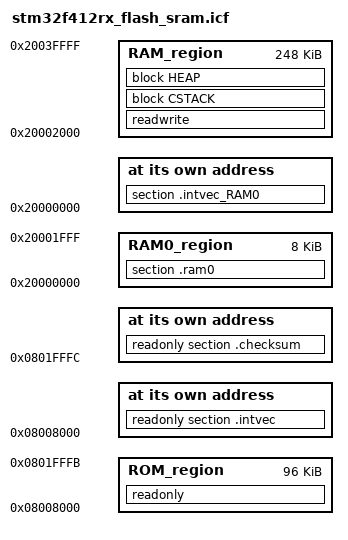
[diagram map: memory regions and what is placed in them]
/*###ICF### Section handled by ICF editor, don't touch! ****/
/*-Editor annotation file-*/
/* IcfEditorFile="$TOOLKIT_DIR$\config\ide\IcfEditor\cortex_v1_0.xml" */
/*-Specials-*/
define symbol __ICFEDIT_intvec_start__ = 0x08008000;
define symbol RAM0_intvec_start        = 0x20000000;

/*-Memory Regions-*/
define symbol __ICFEDIT_region_ROM_start__  = 0x08008000;
define symbol __ICFEDIT_region_ROM_end__    = 0x0801FFFB;
define symbol __ICFEDIT_region_RAM_start__  = 0x20002000;
define symbol __ICFEDIT_region_RAM_end__    = 0x2003FFFF;
define symbol __ICFEDIT_region_RAM0_start__ = 0x20000000;
define symbol __ICFEDIT_region_RAM0_end__   = 0x20001FFF;

/*-Sizes-*/
define symbol __ICFEDIT_size_cstack__ = 0x1400;
define symbol __ICFEDIT_size_heap__   = 0x1200;
/**** End of ICF editor section. ###ICF###*/


define memory mem with size = 4G;
define region ROM_region       = mem:[from __ICFEDIT_region_ROM_start__   to __ICFEDIT_region_ROM_end__];
define region RAM_region       = mem:[from __ICFEDIT_region_RAM_start__   to __ICFEDIT_region_RAM_end__];
define region RAM0_region      = mem:[from __ICFEDIT_region_RAM0_start__   to __ICFEDIT_region_RAM0_end__];

define block CSTACK         with alignment = 8, size = __ICFEDIT_size_cstack__   { };
define block HEAP           with alignment = 8, size = __ICFEDIT_size_heap__     { };

/*initialize by copy { readonly, readwrite };*/
initialize by copy { readwrite,
					section .ram0,
					section .intvec,
					section .intvec_RAM0,
					ro object stm32f4xx_it.o ,
					ro object *.o
					}
					except{
					ro object bl_header.o
					};
do not initialize  { section .noinit };

place at address mem:__ICFEDIT_intvec_start__ { readonly section .intvec };
place at address mem:RAM0_intvec_start { section .intvec_RAM0 };

place in ROM_region   { readonly };
place in RAM_region   { readwrite,
                        block CSTACK, block HEAP };
place in RAM0_region   { section .ram0 };
place at address mem:0x0801FFFC { readonly section .checksum };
